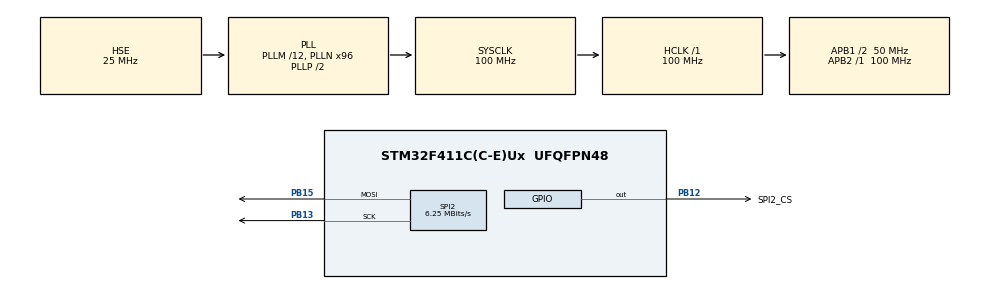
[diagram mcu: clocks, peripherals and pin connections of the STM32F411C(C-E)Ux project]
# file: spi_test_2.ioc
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Mcu.Family=STM32F4
Mcu.Name=STM32F411C(C-E)Ux
Mcu.Package=UFQFPN48
NVIC.PriorityGroup=NVIC_PRIORITYGROUP_4
PB12.GPIO_Label=SPI2_CS
PB12.GPIO_Speed=GPIO_SPEED_FREQ_HIGH
PB12.PinState=GPIO_PIN_SET
PB12.Signal=GPIO_Output
PB13.Mode=TX_Only_Simplex_Unidirect_Master
PB13.Signal=SPI2_SCK
PB15.Mode=TX_Only_Simplex_Unidirect_Master
PB15.Signal=SPI2_MOSI
PC14-OSC32_IN.Mode=LSE-External-Oscillator
PC14-OSC32_IN.Signal=RCC_OSC32_IN
PC15-OSC32_OUT.Mode=LSE-External-Oscillator
PC15-OSC32_OUT.Signal=RCC_OSC32_OUT
PH0\ -\ OSC_IN.Mode=HSE-External-Oscillator
PH0\ -\ OSC_IN.Signal=RCC_OSC_IN
PH1\ -\ OSC_OUT.Mode=HSE-External-Oscillator
PH1\ -\ OSC_OUT.Signal=RCC_OSC_OUT
ProjectManager.HeapSize=0x200
ProjectManager.StackSize=0x400
ProjectManager.TargetToolchain=STM32CubeIDE
RCC.48MHZClocksFreq_Value=50000000
RCC.AHBFreq_Value=100000000
RCC.APB1CLKDivider=RCC_HCLK_DIV2
RCC.APB1Freq_Value=50000000
RCC.APB1TimFreq_Value=100000000
RCC.APB2Freq_Value=100000000
RCC.APB2TimFreq_Value=100000000
RCC.CortexFreq_Value=100000000
RCC.HCLKFreq_Value=100000000
RCC.HSE_VALUE=25000000
RCC.HSI_VALUE=16000000
RCC.PLLM=12
RCC.PLLN=96
RCC.PLLSourceVirtual=RCC_PLLSOURCE_HSE
RCC.SYSCLKFreq_VALUE=100000000
RCC.SYSCLKSource=RCC_SYSCLKSOURCE_PLLCLK
RCC.VCOOutputFreq_Value=200000000
SPI2.BaudRatePrescaler=SPI_BAUDRATEPRESCALER_8
SPI2.CalculateBaudRate=6.25 MBits/s
SPI2.Direction=SPI_DIRECTION_2LINES
SPI2.Mode=SPI_MODE_MASTER
SPI2.VirtualType=VM_MASTER
board=custom

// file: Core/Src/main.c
/* USER CODE BEGIN Header */
/**
  ******************************************************************************
  * @file           : main.c
  * @brief          : Main program body
  ******************************************************************************
  * @attention
  *
  * Copyright (c) 2024 STMicroelectronics.
  * All rights reserved.
  *
  * This software is licensed under terms that can be found in the LICENSE file
  * in the root directory of this software component.
  * If no LICENSE file comes with this software, it is provided AS-IS.
  *
  ******************************************************************************
  */
/* USER CODE END Header */
#include "main.h"
#include "spi.h"
#include "gpio.h"

void SystemClock_Config(void);

/* USER CODE BEGIN 0 */
static void max7219_write(uint8_t addr, uint8_t data)
{
	uint8_t spi_data[] = {addr, data};
	HAL_GPIO_WritePin(SPI2_CS_GPIO_Port, SPI2_CS_Pin, GPIO_PIN_RESET);
	HAL_SPI_Transmit(&hspi2, spi_data, sizeof(spi_data), 1);
	HAL_GPIO_WritePin(SPI2_CS_GPIO_Port, SPI2_CS_Pin, GPIO_PIN_SET);
}

static void max7219_init()
{
  for (uint8_t i = 0; i < 8; i++)     // zero all rows
    max7219_write(0x01 + i, 0x00);

  max7219_write(0x0A, 0x00);     // brightness
  max7219_write(0x0B, 0x07);     // scan limit (8 digits)
  max7219_write(0x09, 0x00);     // decode mode (no BCD decoding)
  max7219_write(0x0F, 0x00);     // disable test mode
  max7219_write(0x0C, 0x01);     // shutdown mode (normal operation)

  max7219_write(0x01, 0x01);     // light up one dot (0,0)
}

static void max7219_set_row(uint8_t row_index)
{
  max7219_write(row_index + 1, 0xFF);
}

static void max7219_set_col(uint8_t col_index)
{
  for (uint8_t i = 0; i < 8; i++)
    max7219_write(i + 1, 0x01 << col_index);
}

static void max7219_clear()
{
  for (uint8_t i = 0; i < 8; i++)
    max7219_write(i + 1, 0x00);
}
/* USER CODE END 0 */

int main(void)
{

  /* MCU Configuration--------------------------------------------------------*/

  /* Reset of all peripherals, Initializes the Flash interface and the Systick. */
  HAL_Init();

  /* Configure the system clock */
  SystemClock_Config();

  /* Initialize all configured peripherals */
  MX_GPIO_Init();
  MX_SPI2_Init();
  /* USER CODE BEGIN 2 */
  max7219_init();
  /* USER CODE END 2 */

  /* Infinite loop */
  /* USER CODE BEGIN WHILE */
  while (1)
  {
	    for (int i = 0; i < 8; i++) {
	      max7219_clear();
	      max7219_set_row(i);
	      HAL_Delay(250);
	    }
	    for (int i = 0; i < 8; i++) {
	      max7219_clear();
	      max7219_set_col(i);
	      HAL_Delay(250);
	    }
    /* USER CODE END WHILE */

  }
}

void SystemClock_Config(void)
{
  RCC_OscInitTypeDef RCC_OscInitStruct = {0};
  RCC_ClkInitTypeDef RCC_ClkInitStruct = {0};

  /** Configure the main internal regulator output voltage
  */
  __HAL_RCC_PWR_CLK_ENABLE();
  __HAL_PWR_VOLTAGESCALING_CONFIG(PWR_REGULATOR_VOLTAGE_SCALE1);

  /** Initializes the RCC Oscillators according to the specified parameters
  * in the RCC_OscInitTypeDef structure.
  */
  RCC_OscInitStruct.OscillatorType = RCC_OSCILLATORTYPE_HSE;
  RCC_OscInitStruct.HSEState = RCC_HSE_ON;
  RCC_OscInitStruct.PLL.PLLState = RCC_PLL_ON;
  RCC_OscInitStruct.PLL.PLLSource = RCC_PLLSOURCE_HSE;
  RCC_OscInitStruct.PLL.PLLM = 12;
  RCC_OscInitStruct.PLL.PLLN = 96;
  RCC_OscInitStruct.PLL.PLLP = RCC_PLLP_DIV2;
  RCC_OscInitStruct.PLL.PLLQ = 4;
  if (HAL_RCC_OscConfig(&RCC_OscInitStruct) != HAL_OK)
  {
    Error_Handler();
  }

  /** Initializes the CPU, AHB and APB buses clocks
  */
  RCC_ClkInitStruct.ClockType = RCC_CLOCKTYPE_HCLK|RCC_CLOCKTYPE_SYSCLK
                              |RCC_CLOCKTYPE_PCLK1|RCC_CLOCKTYPE_PCLK2;
  RCC_ClkInitStruct.SYSCLKSource = RCC_SYSCLKSOURCE_PLLCLK;
  RCC_ClkInitStruct.AHBCLKDivider = RCC_SYSCLK_DIV1;
  RCC_ClkInitStruct.APB1CLKDivider = RCC_HCLK_DIV2;
  RCC_ClkInitStruct.APB2CLKDivider = RCC_HCLK_DIV1;

  if (HAL_RCC_ClockConfig(&RCC_ClkInitStruct, FLASH_LATENCY_3) != HAL_OK)
  {
    Error_Handler();
  }
}

void Error_Handler(void)
{
  __disable_irq();
  while (1)
  {
  }
}
